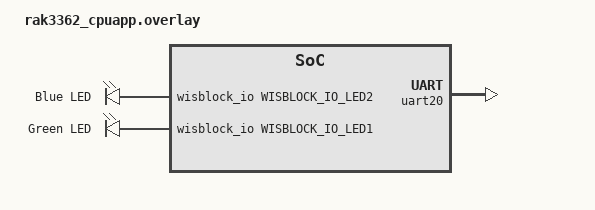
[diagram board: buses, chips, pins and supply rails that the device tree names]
#include <zephyr/dt-bindings/gpio/wisblock-io-slot.h>

/ {
	chosen {
		zephyr,console = &uart20;
		zephyr,uart-mcumgr = &uart20;
	};

	aliases {
		blue-led = &blue_led;
		green-led = &green_led;
	};

	leds {
		compatible = "gpio-leds";
		blue_led: led_2 {
			gpios = <&wisblock_io WISBLOCK_IO_LED2 GPIO_ACTIVE_HIGH>;
			label = "Blue LED";
		};
		green_led: led_1 {
			gpios = <&wisblock_io WISBLOCK_IO_LED1 GPIO_ACTIVE_HIGH>;
			label = "Green LED";
		};
	};
};

&uart20 {
	status = "okay";
};
